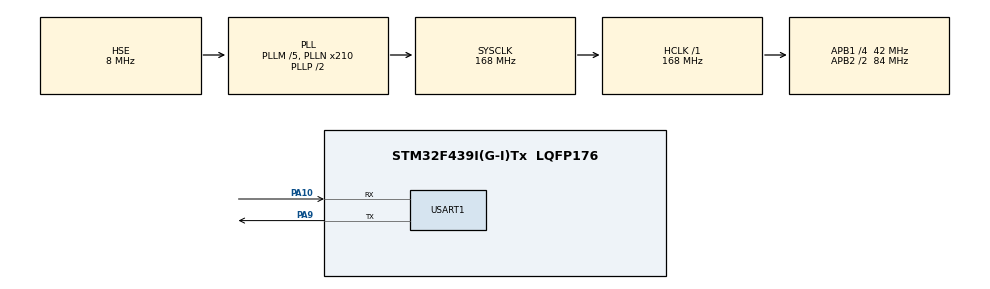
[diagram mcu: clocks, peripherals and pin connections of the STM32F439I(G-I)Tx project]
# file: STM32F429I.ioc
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Dma.Request0=USART1_RX
Dma.Request1=USART1_TX
Dma.USART1_RX.0.Channel=DMA_CHANNEL_4
Dma.USART1_RX.0.Direction=DMA_PERIPH_TO_MEMORY
Dma.USART1_RX.0.FIFOMode=DMA_FIFOMODE_DISABLE
Dma.USART1_RX.0.Instance=DMA2_Stream2
Dma.USART1_RX.0.MemDataAlignment=DMA_MDATAALIGN_BYTE
Dma.USART1_RX.0.MemInc=DMA_MINC_ENABLE
Dma.USART1_RX.0.Mode=DMA_NORMAL
Dma.USART1_RX.0.PeriphDataAlignment=DMA_PDATAALIGN_BYTE
Dma.USART1_RX.0.PeriphInc=DMA_PINC_DISABLE
Dma.USART1_RX.0.Priority=DMA_PRIORITY_LOW
Dma.USART1_TX.1.Channel=DMA_CHANNEL_4
Dma.USART1_TX.1.Direction=DMA_MEMORY_TO_PERIPH
Dma.USART1_TX.1.FIFOMode=DMA_FIFOMODE_ENABLE
Dma.USART1_TX.1.FIFOThreshold=DMA_FIFO_THRESHOLD_FULL
Dma.USART1_TX.1.Instance=DMA2_Stream7
Dma.USART1_TX.1.MemBurst=DMA_MBURST_SINGLE
Dma.USART1_TX.1.MemDataAlignment=DMA_MDATAALIGN_BYTE
Dma.USART1_TX.1.MemInc=DMA_MINC_ENABLE
Dma.USART1_TX.1.Mode=DMA_NORMAL
Dma.USART1_TX.1.PeriphBurst=DMA_PBURST_SINGLE
Dma.USART1_TX.1.PeriphDataAlignment=DMA_PDATAALIGN_BYTE
Dma.USART1_TX.1.PeriphInc=DMA_PINC_DISABLE
Dma.USART1_TX.1.Priority=DMA_PRIORITY_LOW
Mcu.Family=STM32F4
Mcu.Name=STM32F439I(G-I)Tx
Mcu.Package=LQFP176
NVIC.DMA2_Stream2_IRQn=true\:0\:0\:false
NVIC.DMA2_Stream7_IRQn=true\:0\:0\:false
NVIC.PriorityGroup=NVIC_PRIORITYGROUP_4
NVIC.USART1_IRQn=true\:0\:0\:false
PA10.Mode=Asynchronous
PA10.Signal=USART1_RX
PA9.Mode=Asynchronous
PA9.Signal=USART1_TX
PH0/OSC_IN.Mode=HSE-External-Oscillator
PH0/OSC_IN.Signal=RCC_OSC_IN
PH1/OSC_OUT.Mode=HSE-External-Oscillator
PH1/OSC_OUT.Signal=RCC_OSC_OUT
ProjectManager.TargetToolchain=MDK-ARM V5
RCC.48MHZClocksFreq_Value=84000000
RCC.AHBFreq_Value=168000000
RCC.APB1CLKDivider=RCC_HCLK_DIV4
RCC.APB1Freq_Value=42000000
RCC.APB1TimFreq_Value=84000000
RCC.APB2CLKDivider=RCC_HCLK_DIV2
RCC.APB2Freq_Value=84000000
RCC.APB2TimFreq_Value=168000000
RCC.CortexFreq_Value=168000000
RCC.HCLKFreq_Value=168000000
RCC.HSE_VALUE=8000000
RCC.HSI_VALUE=16000000
RCC.LSE_VALUE=32768
RCC.PLLM=5
RCC.PLLN=210
RCC.PLLSourceVirtual=RCC_PLLSOURCE_HSE
RCC.SYSCLKFreq_VALUE=168000000
RCC.SYSCLKSource=RCC_SYSCLKSOURCE_PLLCLK
RCC.VCOOutputFreq_Value=336000000
board=STM32F429I

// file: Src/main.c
/**
  ******************************************************************************
  * File Name          : main.c
  * Description        : Main program body
  ******************************************************************************
  *
  * COPYRIGHT(c) 2015 STMicroelectronics
  *
  * Redistribution and use in source and binary forms, with or without modification,
  * are permitted provided that the following conditions are met:
  *   1. Redistributions of source code must retain the above copyright notice,
  *      this list of conditions and the following disclaimer.
  *   2. Redistributions in binary form must reproduce the above copyright notice,
  *      this list of conditions and the following disclaimer in the documentation
  *      and/or other materials provided with the distribution.
  *   3. Neither the name of STMicroelectronics nor the names of its contributors
  *      may be used to endorse or promote products derived from this software
  *      without specific prior written permission.
  *
  * THIS SOFTWARE IS PROVIDED BY THE COPYRIGHT HOLDERS AND CONTRIBUTORS "AS IS"
  * AND ANY EXPRESS OR IMPLIED WARRANTIES, INCLUDING, BUT NOT LIMITED TO, THE
  * IMPLIED WARRANTIES OF MERCHANTABILITY AND FITNESS FOR A PARTICULAR PURPOSE ARE
  * DISCLAIMED. IN NO EVENT SHALL THE COPYRIGHT HOLDER OR CONTRIBUTORS BE LIABLE
  * FOR ANY DIRECT, INDIRECT, INCIDENTAL, SPECIAL, EXEMPLARY, OR CONSEQUENTIAL
  * DAMAGES (INCLUDING, BUT NOT LIMITED TO, PROCUREMENT OF SUBSTITUTE GOODS OR
  * SERVICES; LOSS OF USE, DATA, OR PROFITS; OR BUSINESS INTERRUPTION) HOWEVER
  * CAUSED AND ON ANY THEORY OF LIABILITY, WHETHER IN CONTRACT, STRICT LIABILITY,
  * OR TORT (INCLUDING NEGLIGENCE OR OTHERWISE) ARISING IN ANY WAY OUT OF THE USE
  * OF THIS SOFTWARE, EVEN IF ADVISED OF THE POSSIBILITY OF SUCH DAMAGE.
  *
  ******************************************************************************
  */
#include "stm32f4xx_hal.h"
#include "dma.h"
#include "usart.h"
#include "gpio.h"

/* USER CODE BEGIN PV */
/* Private variables ---------------------------------------------------------*/
/* Buffer used for transmission */
uint8_t aTxStartMessage[] = "\r\n ****UART-Hyperterminal communication based on IT ****\r\n Enter 10 characters using keyboard :\r\n";
uint8_t aTxEndMessage[] = "\r\n Example Finished\r\n";

/* Buffer used for reception */
uint8_t aRxBuffer[20];

/* USER CODE END PV */

void SystemClock_Config(void);

/* USER CODE BEGIN PFP */
/* Private function prototypes -----------------------------------------------*/

/* USER CODE END PFP */

int main(void)
{

  /* MCU Configuration----------------------------------------------------------*/

  /* Reset of all peripherals, Initializes the Flash interface and the Systick. */
  HAL_Init();

  /* Configure the system clock */
  SystemClock_Config();

  /* Initialize all configured peripherals */
  MX_GPIO_Init();
  MX_DMA_Init();
  MX_USART1_UART_Init();

  /* USER CODE BEGIN 2 */
	  /*##-1- Start the transmission process #####################################*/
  /* While the UART in reception process, user can transmit data through
     "aTxBuffer" buffer */
  if(HAL_UART_Transmit_IT(&huart1, (uint8_t *)aTxStartMessage, sizeof(aTxStartMessage))!= HAL_OK)
  {
    /* Turn LED3 on: Transfer error in transmission process */
    while(1)
    {
    }
  }

  /*##-2- Put UART peripheral in reception process ###########################*/
  /* Any data received will be stored "aRxBuffer" buffer : the number max of
     data received is 10 */
  if(HAL_UART_Receive_IT(&huart1, (uint8_t *)aRxBuffer, 10) != HAL_OK)
  {
    /* Turn LED3 on: Transfer error in reception process */
    while(1)
    {
    }
  }

  /*##-3- Wait for the end of the transfer ###################################*/
  /*  Before starting a new communication transfer, you need to check the current
      state of the peripheral; if itТs busy you need to wait for the end of current
      transfer before starting a new one.
      For simplicity reasons, this example is just waiting till the end of the
      transfer, but application may perform other tasks while transfer operation
      is ongoing. */
  while (HAL_UART_GetState(&huart1) != HAL_UART_STATE_READY)
  {
  }

  /*##-4- Send the received Buffer ###########################################*/
  if(HAL_UART_Transmit_IT(&huart1, (uint8_t *)aRxBuffer, 10)!= HAL_OK)
  {
    /* Turn LED3 on: Transfer error in transmission process */
    while(1)
    {
    }
  }

  /*##-5- Wait for the end of the transfer ###################################*/
  /*  Before starting a new communication transfer, you need to check the current
      state of the peripheral; if itТs busy you need to wait for the end of current
      transfer before starting a new one.
      For simplicity reasons, this example is just waiting till the end of the
      transfer, but application may perform other tasks while transfer operation
      is ongoing. */
  while (HAL_UART_GetState(&huart1) != HAL_UART_STATE_READY)
  {
  }

	HAL_Delay(100);
  /*##-6- Send the End Message ###############################################*/
  if(HAL_UART_Transmit_IT(&huart1, (uint8_t*)aTxEndMessage, sizeof(aTxEndMessage))!= HAL_OK)
  {
    /* Turn LED3 on: Transfer error in transmission process */
    while(1)
    {
    }
  }

  /*##-7- Wait for the end of the transfer ###################################*/
  while (HAL_UART_GetState(&huart1) != HAL_UART_STATE_READY)
  {
  }
  /* USER CODE END 2 */

  /* Infinite loop */
  while (1)
  {

  }

}

/** System Clock Configuration
*/
void SystemClock_Config(void)
{

  RCC_OscInitTypeDef RCC_OscInitStruct;
  RCC_ClkInitTypeDef RCC_ClkInitStruct;

  __PWR_CLK_ENABLE();

  __HAL_PWR_VOLTAGESCALING_CONFIG(PWR_REGULATOR_VOLTAGE_SCALE1);

  RCC_OscInitStruct.OscillatorType = RCC_OSCILLATORTYPE_HSE;
  RCC_OscInitStruct.HSEState = RCC_HSE_ON;
  RCC_OscInitStruct.PLL.PLLState = RCC_PLL_ON;
  RCC_OscInitStruct.PLL.PLLSource = RCC_PLLSOURCE_HSE;
  RCC_OscInitStruct.PLL.PLLM = 5;
  RCC_OscInitStruct.PLL.PLLN = 210;
  RCC_OscInitStruct.PLL.PLLP = RCC_PLLP_DIV2;
  RCC_OscInitStruct.PLL.PLLQ = 4;
  HAL_RCC_OscConfig(&RCC_OscInitStruct);

  RCC_ClkInitStruct.ClockType = RCC_CLOCKTYPE_SYSCLK|RCC_CLOCKTYPE_PCLK1
                              |RCC_CLOCKTYPE_PCLK2;
  RCC_ClkInitStruct.SYSCLKSource = RCC_SYSCLKSOURCE_PLLCLK;
  RCC_ClkInitStruct.AHBCLKDivider = RCC_SYSCLK_DIV1;
  RCC_ClkInitStruct.APB1CLKDivider = RCC_HCLK_DIV4;
  RCC_ClkInitStruct.APB2CLKDivider = RCC_HCLK_DIV2;
  HAL_RCC_ClockConfig(&RCC_ClkInitStruct, FLASH_LATENCY_5);

  HAL_SYSTICK_Config(HAL_RCC_GetHCLKFreq()/1000);

  HAL_SYSTICK_CLKSourceConfig(SYSTICK_CLKSOURCE_HCLK);

  /* SysTick_IRQn interrupt configuration */
  HAL_NVIC_SetPriority(SysTick_IRQn, 0, 0);
}

/************************ (C) COPYRIGHT STMicroelectronics *****END OF FILE****/
